VERSION ""

NS_ :

BS_:

BU_: XXX

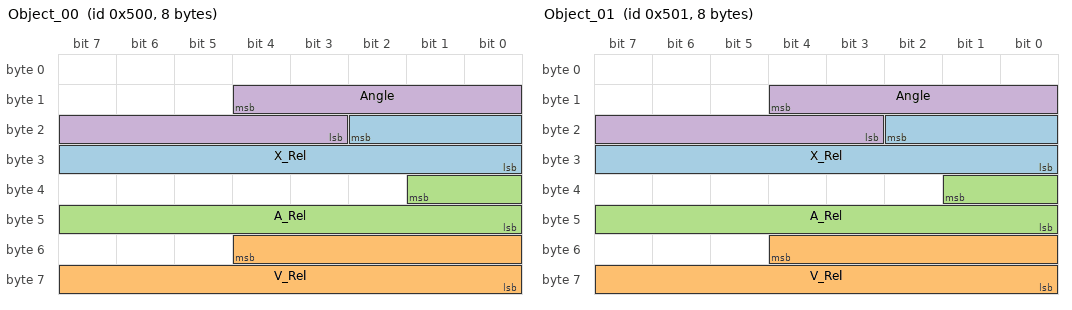
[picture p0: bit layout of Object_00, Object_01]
BO_ 1280 Object_00: 8 XXX
 SG_ X_Rel : 18|11@0+ (0.1,0) [0|0] "m" XXX
 SG_ V_Rel : 52|13@0- (0.01,0) [0|0] "m/s" XXX
 SG_ A_Rel : 33|10@0- (0.05,0) [0|0] "m/s2" XXX
 SG_ Angle : 12|10@0- (-0.1,0) [0|0] "deg" XXX

BO_ 1281 Object_01: 8 XXX
 SG_ X_Rel : 18|11@0+ (0.1,0) [0|0] "m" XXX
 SG_ V_Rel : 52|13@0- (0.01,0) [0|0] "m/s" XXX
 SG_ A_Rel : 33|10@0- (0.05,0) [0|0] "m/s2" XXX
 SG_ Angle : 12|10@0- (-0.1,0) [0|0] "deg" XXX

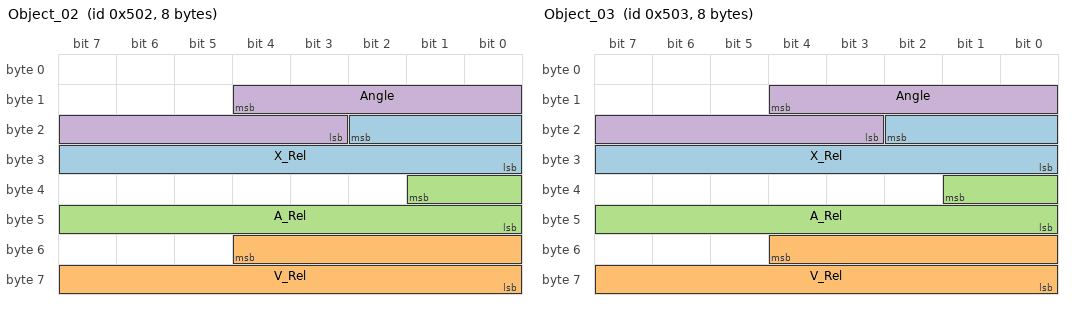
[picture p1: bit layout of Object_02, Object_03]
BO_ 1282 Object_02: 8 XXX
 SG_ X_Rel : 18|11@0+ (0.1,0) [0|0] "m" XXX
 SG_ V_Rel : 52|13@0- (0.01,0) [0|0] "m/s" XXX
 SG_ A_Rel : 33|10@0- (0.05,0) [0|0] "m/s2" XXX
 SG_ Angle : 12|10@0- (-0.1,0) [0|0] "deg" XXX

BO_ 1283 Object_03: 8 XXX
 SG_ X_Rel : 18|11@0+ (0.1,0) [0|0] "m" XXX
 SG_ V_Rel : 52|13@0- (0.01,0) [0|0] "m/s" XXX
 SG_ A_Rel : 33|10@0- (0.05,0) [0|0] "m/s2" XXX
 SG_ Angle : 12|10@0- (-0.1,0) [0|0] "deg" XXX

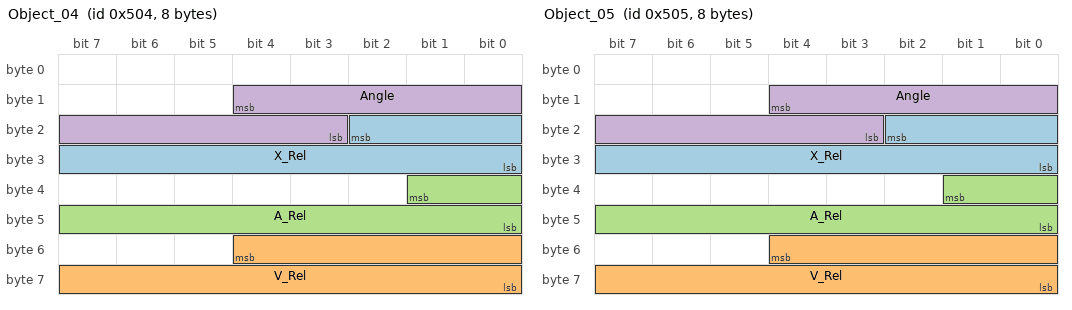
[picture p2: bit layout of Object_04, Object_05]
BO_ 1284 Object_04: 8 XXX
 SG_ X_Rel : 18|11@0+ (0.1,0) [0|0] "m" XXX
 SG_ V_Rel : 52|13@0- (0.01,0) [0|0] "m/s" XXX
 SG_ A_Rel : 33|10@0- (0.05,0) [0|0] "m/s2" XXX
 SG_ Angle : 12|10@0- (-0.1,0) [0|0] "deg" XXX

BO_ 1285 Object_05: 8 XXX
 SG_ X_Rel : 18|11@0+ (0.1,0) [0|0] "m" XXX
 SG_ V_Rel : 52|13@0- (0.01,0) [0|0] "m/s" XXX
 SG_ A_Rel : 33|10@0- (0.05,0) [0|0] "m/s2" XXX
 SG_ Angle : 12|10@0- (-0.1,0) [0|0] "deg" XXX

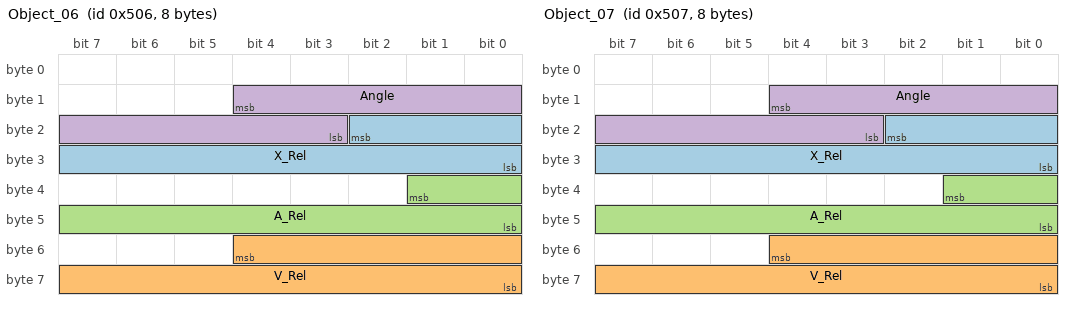
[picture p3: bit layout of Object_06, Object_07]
BO_ 1286 Object_06: 8 XXX
 SG_ X_Rel : 18|11@0+ (0.1,0) [0|0] "m" XXX
 SG_ V_Rel : 52|13@0- (0.01,0) [0|0] "m/s" XXX
 SG_ A_Rel : 33|10@0- (0.05,0) [0|0] "m/s2" XXX
 SG_ Angle : 12|10@0- (-0.1,0) [0|0] "deg" XXX

BO_ 1287 Object_07: 8 XXX
 SG_ X_Rel : 18|11@0+ (0.1,0) [0|0] "m" XXX
 SG_ V_Rel : 52|13@0- (0.01,0) [0|0] "m/s" XXX
 SG_ A_Rel : 33|10@0- (0.05,0) [0|0] "m/s2" XXX
 SG_ Angle : 12|10@0- (-0.1,0) [0|0] "deg" XXX

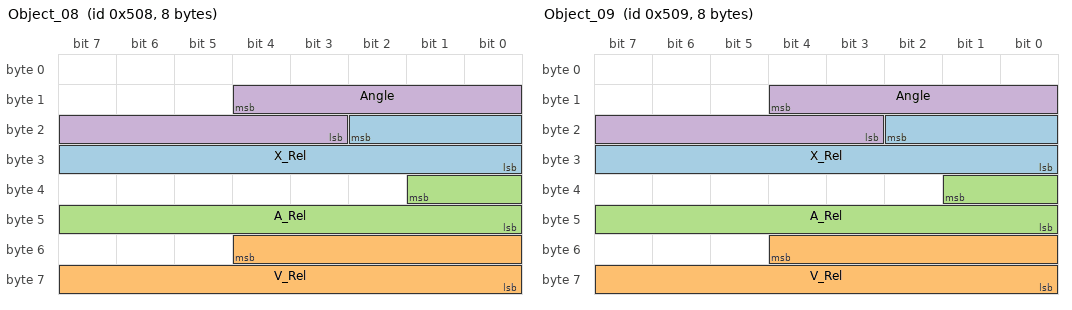
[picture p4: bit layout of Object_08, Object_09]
BO_ 1288 Object_08: 8 XXX
 SG_ X_Rel : 18|11@0+ (0.1,0) [0|0] "m" XXX
 SG_ V_Rel : 52|13@0- (0.01,0) [0|0] "m/s" XXX
 SG_ A_Rel : 33|10@0- (0.05,0) [0|0] "m/s2" XXX
 SG_ Angle : 12|10@0- (-0.1,0) [0|0] "deg" XXX

BO_ 1289 Object_09: 8 XXX
 SG_ X_Rel : 18|11@0+ (0.1,0) [0|0] "m" XXX
 SG_ V_Rel : 52|13@0- (0.01,0) [0|0] "m/s" XXX
 SG_ A_Rel : 33|10@0- (0.05,0) [0|0] "m/s2" XXX
 SG_ Angle : 12|10@0- (-0.1,0) [0|0] "deg" XXX

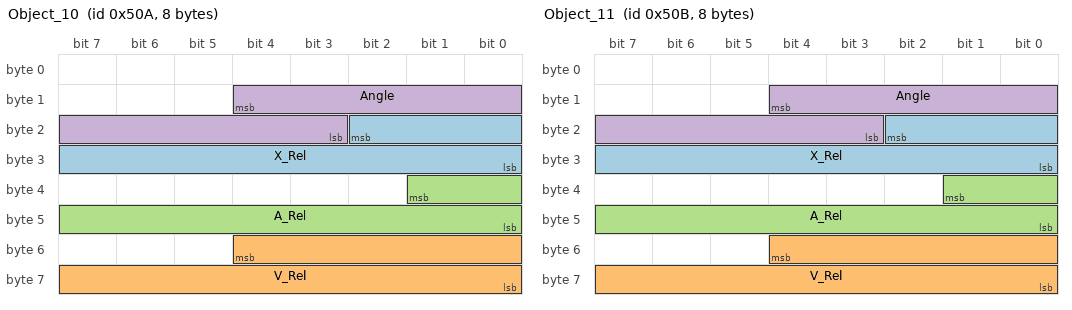
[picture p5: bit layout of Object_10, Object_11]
BO_ 1290 Object_10: 8 XXX
 SG_ X_Rel : 18|11@0+ (0.1,0) [0|0] "m" XXX
 SG_ V_Rel : 52|13@0- (0.01,0) [0|0] "m/s" XXX
 SG_ A_Rel : 33|10@0- (0.05,0) [0|0] "m/s2" XXX
 SG_ Angle : 12|10@0- (-0.1,0) [0|0] "deg" XXX

BO_ 1291 Object_11: 8 XXX
 SG_ X_Rel : 18|11@0+ (0.1,0) [0|0] "m" XXX
 SG_ V_Rel : 52|13@0- (0.01,0) [0|0] "m/s" XXX
 SG_ A_Rel : 33|10@0- (0.05,0) [0|0] "m/s2" XXX
 SG_ Angle : 12|10@0- (-0.1,0) [0|0] "deg" XXX

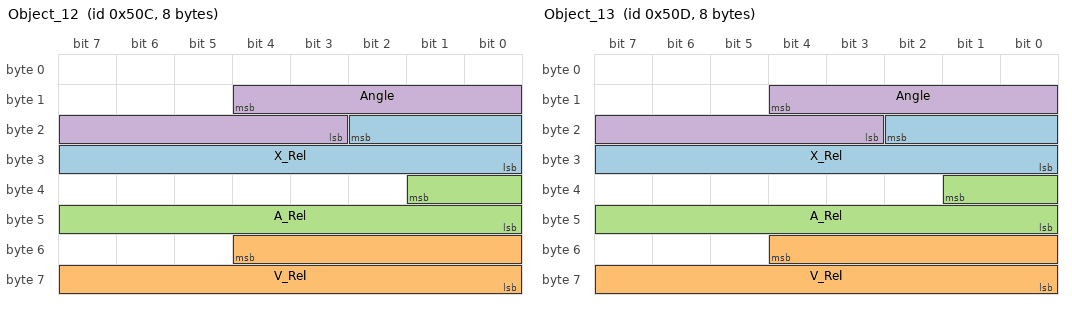
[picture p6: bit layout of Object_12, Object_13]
BO_ 1292 Object_12: 8 XXX
 SG_ X_Rel : 18|11@0+ (0.1,0) [0|0] "m" XXX
 SG_ V_Rel : 52|13@0- (0.01,0) [0|0] "m/s" XXX
 SG_ A_Rel : 33|10@0- (0.05,0) [0|0] "m/s2" XXX
 SG_ Angle : 12|10@0- (-0.1,0) [0|0] "deg" XXX

BO_ 1293 Object_13: 8 XXX
 SG_ X_Rel : 18|11@0+ (0.1,0) [0|0] "m" XXX
 SG_ V_Rel : 52|13@0- (0.01,0) [0|0] "m/s" XXX
 SG_ A_Rel : 33|10@0- (0.05,0) [0|0] "m/s2" XXX
 SG_ Angle : 12|10@0- (-0.1,0) [0|0] "deg" XXX

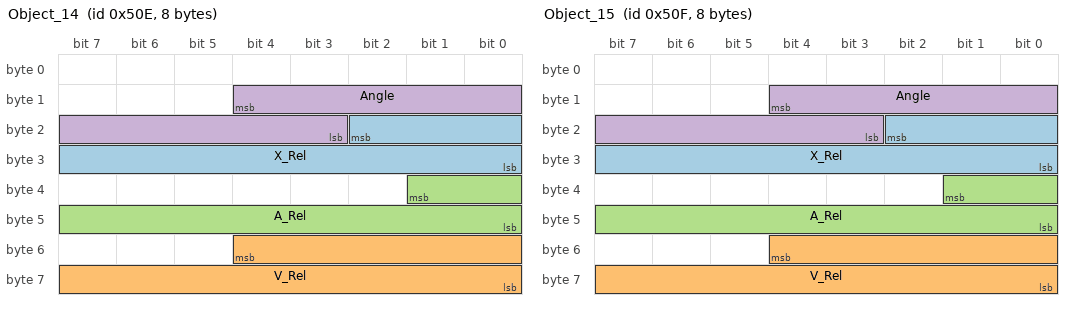
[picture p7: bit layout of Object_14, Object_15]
BO_ 1294 Object_14: 8 XXX
 SG_ X_Rel : 18|11@0+ (0.1,0) [0|0] "m" XXX
 SG_ V_Rel : 52|13@0- (0.01,0) [0|0] "m/s" XXX
 SG_ A_Rel : 33|10@0- (0.05,0) [0|0] "m/s2" XXX
 SG_ Angle : 12|10@0- (-0.1,0) [0|0] "deg" XXX

BO_ 1295 Object_15: 8 XXX
 SG_ X_Rel : 18|11@0+ (0.1,0) [0|0] "m" XXX
 SG_ V_Rel : 52|13@0- (0.01,0) [0|0] "m/s" XXX
 SG_ A_Rel : 33|10@0- (0.05,0) [0|0] "m/s2" XXX
 SG_ Angle : 12|10@0- (-0.1,0) [0|0] "deg" XXX

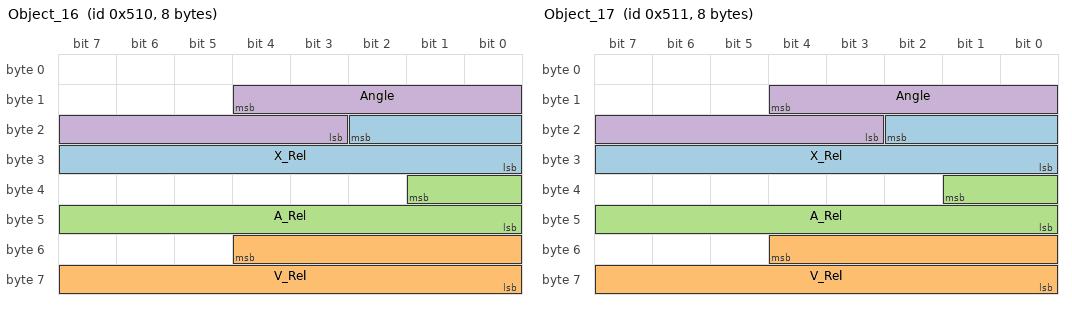
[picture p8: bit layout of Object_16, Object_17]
BO_ 1296 Object_16: 8 XXX
 SG_ X_Rel : 18|11@0+ (0.1,0) [0|0] "m" XXX
 SG_ V_Rel : 52|13@0- (0.01,0) [0|0] "m/s" XXX
 SG_ A_Rel : 33|10@0- (0.05,0) [0|0] "m/s2" XXX
 SG_ Angle : 12|10@0- (-0.1,0) [0|0] "deg" XXX

BO_ 1297 Object_17: 8 XXX
 SG_ X_Rel : 18|11@0+ (0.1,0) [0|0] "m" XXX
 SG_ V_Rel : 52|13@0- (0.01,0) [0|0] "m/s" XXX
 SG_ A_Rel : 33|10@0- (0.05,0) [0|0] "m/s2" XXX
 SG_ Angle : 12|10@0- (-0.1,0) [0|0] "deg" XXX

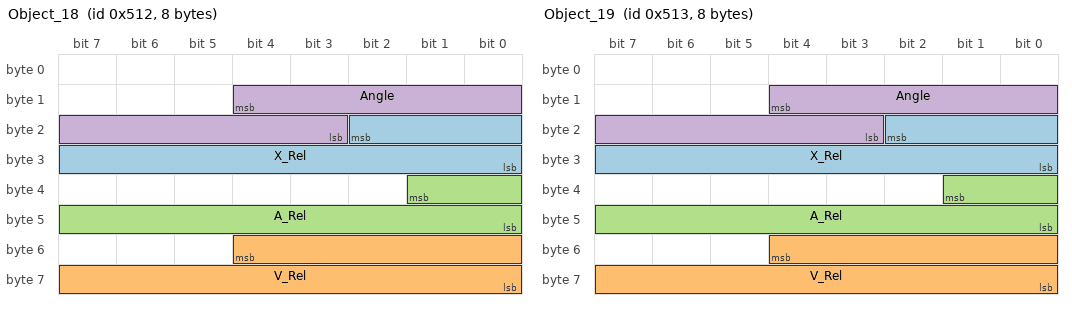
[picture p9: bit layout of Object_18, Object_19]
BO_ 1298 Object_18: 8 XXX
 SG_ X_Rel : 18|11@0+ (0.1,0) [0|0] "m" XXX
 SG_ V_Rel : 52|13@0- (0.01,0) [0|0] "m/s" XXX
 SG_ A_Rel : 33|10@0- (0.05,0) [0|0] "m/s2" XXX
 SG_ Angle : 12|10@0- (-0.1,0) [0|0] "deg" XXX

BO_ 1299 Object_19: 8 XXX
 SG_ X_Rel : 18|11@0+ (0.1,0) [0|0] "m" XXX
 SG_ V_Rel : 52|13@0- (0.01,0) [0|0] "m/s" XXX
 SG_ A_Rel : 33|10@0- (0.05,0) [0|0] "m/s2" XXX
 SG_ Angle : 12|10@0- (-0.1,0) [0|0] "deg" XXX

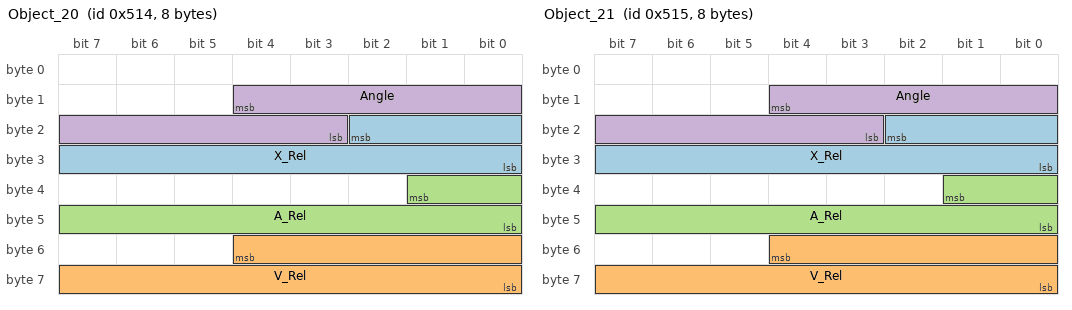
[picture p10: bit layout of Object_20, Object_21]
BO_ 1300 Object_20: 8 XXX
 SG_ X_Rel : 18|11@0+ (0.1,0) [0|0] "m" XXX
 SG_ V_Rel : 52|13@0- (0.01,0) [0|0] "m/s" XXX
 SG_ A_Rel : 33|10@0- (0.05,0) [0|0] "m/s2" XXX
 SG_ Angle : 12|10@0- (-0.1,0) [0|0] "deg" XXX

BO_ 1301 Object_21: 8 XXX
 SG_ X_Rel : 18|11@0+ (0.1,0) [0|0] "m" XXX
 SG_ V_Rel : 52|13@0- (0.01,0) [0|0] "m/s" XXX
 SG_ A_Rel : 33|10@0- (0.05,0) [0|0] "m/s2" XXX
 SG_ Angle : 12|10@0- (-0.1,0) [0|0] "deg" XXX

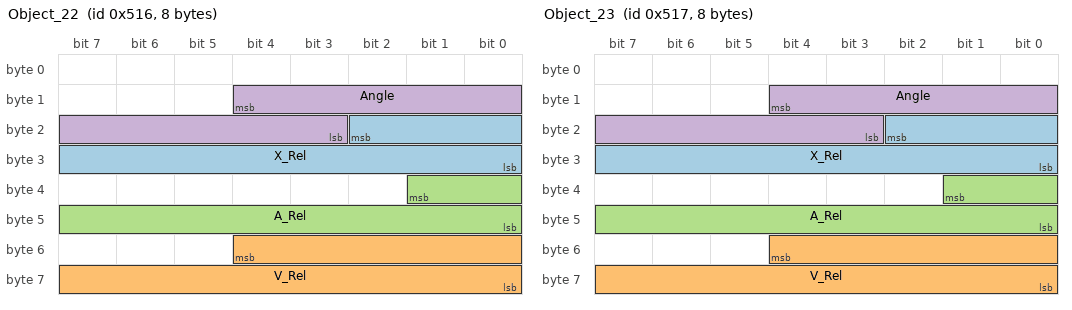
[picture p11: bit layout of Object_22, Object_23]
BO_ 1302 Object_22: 8 XXX
 SG_ X_Rel : 18|11@0+ (0.1,0) [0|0] "m" XXX
 SG_ V_Rel : 52|13@0- (0.01,0) [0|0] "m/s" XXX
 SG_ A_Rel : 33|10@0- (0.05,0) [0|0] "m/s2" XXX
 SG_ Angle : 12|10@0- (-0.1,0) [0|0] "deg" XXX

BO_ 1303 Object_23: 8 XXX
 SG_ X_Rel : 18|11@0+ (0.1,0) [0|0] "m" XXX
 SG_ V_Rel : 52|13@0- (0.01,0) [0|0] "m/s" XXX
 SG_ A_Rel : 33|10@0- (0.05,0) [0|0] "m/s2" XXX
 SG_ Angle : 12|10@0- (-0.1,0) [0|0] "deg" XXX

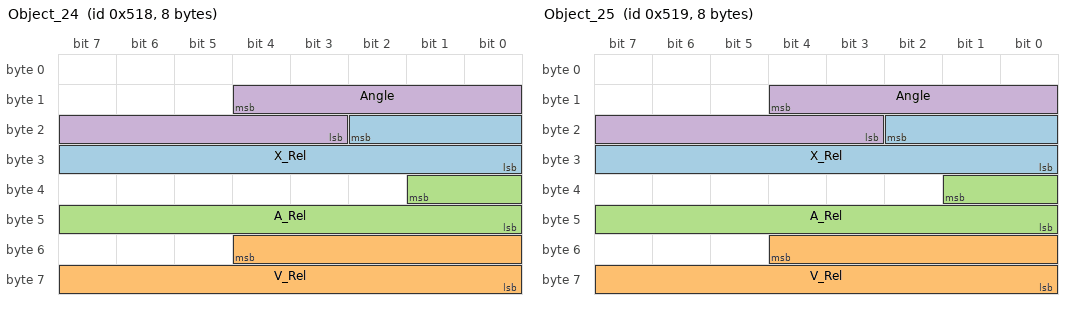
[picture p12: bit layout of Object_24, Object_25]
BO_ 1304 Object_24: 8 XXX
 SG_ X_Rel : 18|11@0+ (0.1,0) [0|0] "m" XXX
 SG_ V_Rel : 52|13@0- (0.01,0) [0|0] "m/s" XXX
 SG_ A_Rel : 33|10@0- (0.05,0) [0|0] "m/s2" XXX
 SG_ Angle : 12|10@0- (-0.1,0) [0|0] "deg" XXX

BO_ 1305 Object_25: 8 XXX
 SG_ X_Rel : 18|11@0+ (0.1,0) [0|0] "m" XXX
 SG_ V_Rel : 52|13@0- (0.01,0) [0|0] "m/s" XXX
 SG_ A_Rel : 33|10@0- (0.05,0) [0|0] "m/s2" XXX
 SG_ Angle : 12|10@0- (-0.1,0) [0|0] "deg" XXX

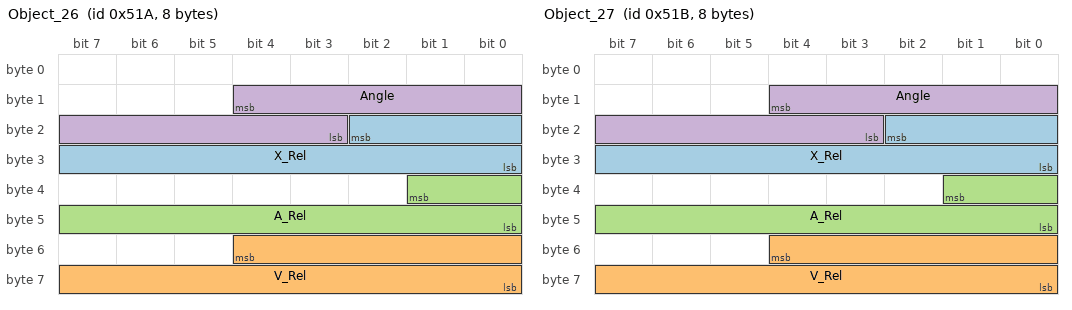
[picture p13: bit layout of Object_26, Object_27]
BO_ 1306 Object_26: 8 XXX
 SG_ X_Rel : 18|11@0+ (0.1,0) [0|0] "m" XXX
 SG_ V_Rel : 52|13@0- (0.01,0) [0|0] "m/s" XXX
 SG_ A_Rel : 33|10@0- (0.05,0) [0|0] "m/s2" XXX
 SG_ Angle : 12|10@0- (-0.1,0) [0|0] "deg" XXX

BO_ 1307 Object_27: 8 XXX
 SG_ X_Rel : 18|11@0+ (0.1,0) [0|0] "m" XXX
 SG_ V_Rel : 52|13@0- (0.01,0) [0|0] "m/s" XXX
 SG_ A_Rel : 33|10@0- (0.05,0) [0|0] "m/s2" XXX
 SG_ Angle : 12|10@0- (-0.1,0) [0|0] "deg" XXX

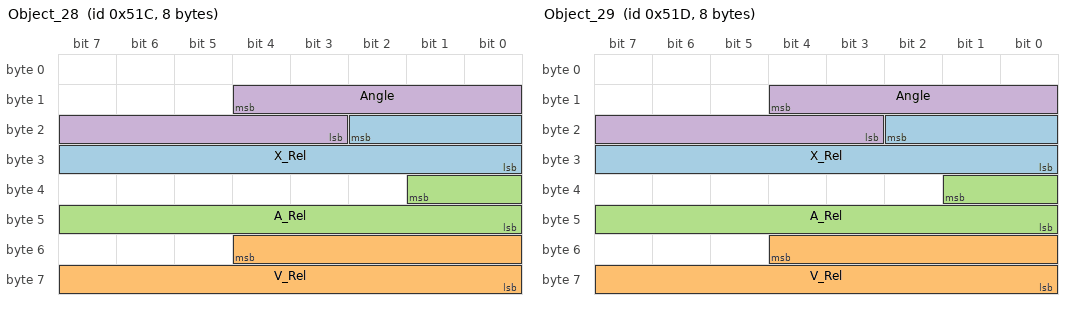
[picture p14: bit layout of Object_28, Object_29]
BO_ 1308 Object_28: 8 XXX
 SG_ X_Rel : 18|11@0+ (0.1,0) [0|0] "m" XXX
 SG_ V_Rel : 52|13@0- (0.01,0) [0|0] "m/s" XXX
 SG_ A_Rel : 33|10@0- (0.05,0) [0|0] "m/s2" XXX
 SG_ Angle : 12|10@0- (-0.1,0) [0|0] "deg" XXX

BO_ 1309 Object_29: 8 XXX
 SG_ X_Rel : 18|11@0+ (0.1,0) [0|0] "m" XXX
 SG_ V_Rel : 52|13@0- (0.01,0) [0|0] "m/s" XXX
 SG_ A_Rel : 33|10@0- (0.05,0) [0|0] "m/s2" XXX
 SG_ Angle : 12|10@0- (-0.1,0) [0|0] "deg" XXX

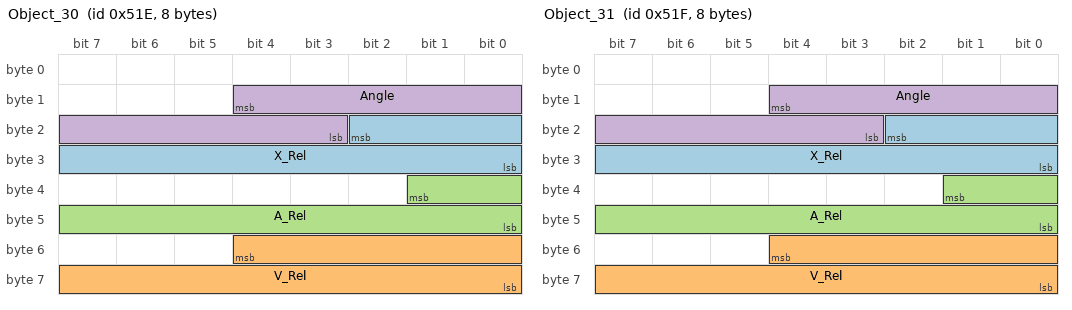
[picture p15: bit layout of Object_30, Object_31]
BO_ 1310 Object_30: 8 XXX
 SG_ X_Rel : 18|11@0+ (0.1,0) [0|0] "m" XXX
 SG_ V_Rel : 52|13@0- (0.01,0) [0|0] "m/s" XXX
 SG_ A_Rel : 33|10@0- (0.05,0) [0|0] "m/s2" XXX
 SG_ Angle : 12|10@0- (-0.1,0) [0|0] "deg" XXX

BO_ 1311 Object_31: 8 XXX
 SG_ X_Rel : 18|11@0+ (0.1,0) [0|0] "m" XXX
 SG_ V_Rel : 52|13@0- (0.01,0) [0|0] "m/s" XXX
 SG_ A_Rel : 33|10@0- (0.05,0) [0|0] "m/s2" XXX
 SG_ Angle : 12|10@0- (-0.1,0) [0|0] "deg" XXX

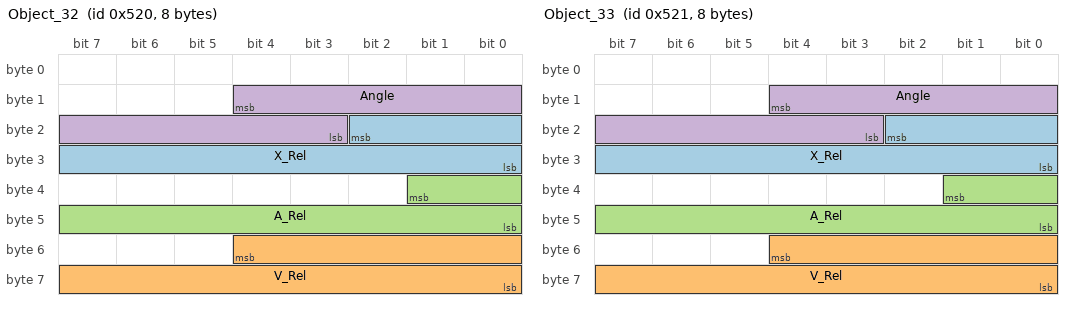
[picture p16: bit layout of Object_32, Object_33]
BO_ 1312 Object_32: 8 XXX
 SG_ X_Rel : 18|11@0+ (0.1,0) [0|0] "m" XXX
 SG_ V_Rel : 52|13@0- (0.01,0) [0|0] "m/s" XXX
 SG_ A_Rel : 33|10@0- (0.05,0) [0|0] "m/s2" XXX
 SG_ Angle : 12|10@0- (-0.1,0) [0|0] "deg" XXX

BO_ 1313 Object_33: 8 XXX
 SG_ X_Rel : 18|11@0+ (0.1,0) [0|0] "m" XXX
 SG_ V_Rel : 52|13@0- (0.01,0) [0|0] "m/s" XXX
 SG_ A_Rel : 33|10@0- (0.05,0) [0|0] "m/s2" XXX
 SG_ Angle : 12|10@0- (-0.1,0) [0|0] "deg" XXX

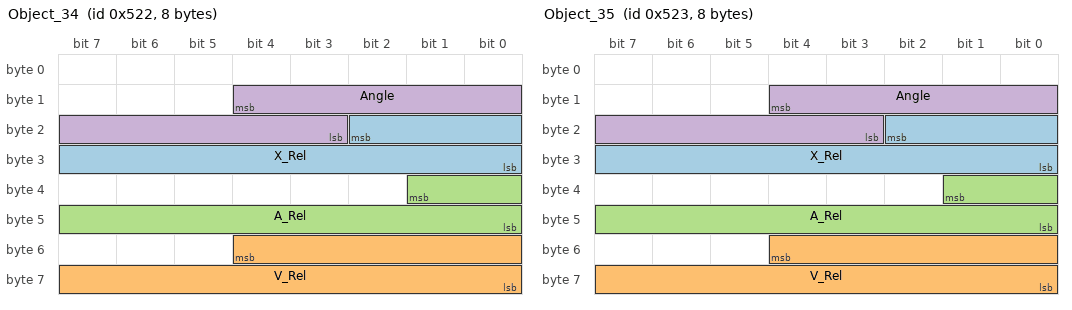
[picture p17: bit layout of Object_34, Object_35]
BO_ 1314 Object_34: 8 XXX
 SG_ X_Rel : 18|11@0+ (0.1,0) [0|0] "m" XXX
 SG_ V_Rel : 52|13@0- (0.01,0) [0|0] "m/s" XXX
 SG_ A_Rel : 33|10@0- (0.05,0) [0|0] "m/s2" XXX
 SG_ Angle : 12|10@0- (-0.1,0) [0|0] "deg" XXX

BO_ 1315 Object_35: 8 XXX
 SG_ X_Rel : 18|11@0+ (0.1,0) [0|0] "m" XXX
 SG_ V_Rel : 52|13@0- (0.01,0) [0|0] "m/s" XXX
 SG_ A_Rel : 33|10@0- (0.05,0) [0|0] "m/s2" XXX
 SG_ Angle : 12|10@0- (-0.1,0) [0|0] "deg" XXX

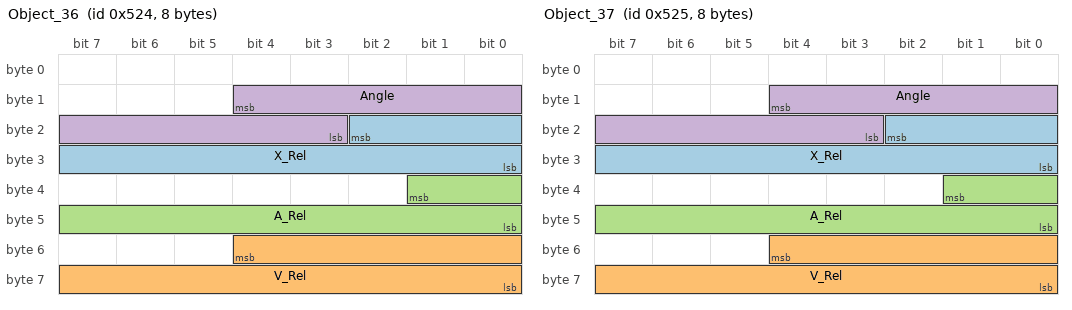
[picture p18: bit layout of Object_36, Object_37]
BO_ 1316 Object_36: 8 XXX
 SG_ X_Rel : 18|11@0+ (0.1,0) [0|0] "m" XXX
 SG_ V_Rel : 52|13@0- (0.01,0) [0|0] "m/s" XXX
 SG_ A_Rel : 33|10@0- (0.05,0) [0|0] "m/s2" XXX
 SG_ Angle : 12|10@0- (-0.1,0) [0|0] "deg" XXX

BO_ 1317 Object_37: 8 XXX
 SG_ X_Rel : 18|11@0+ (0.1,0) [0|0] "m" XXX
 SG_ V_Rel : 52|13@0- (0.01,0) [0|0] "m/s" XXX
 SG_ A_Rel : 33|10@0- (0.05,0) [0|0] "m/s2" XXX
 SG_ Angle : 12|10@0- (-0.1,0) [0|0] "deg" XXX

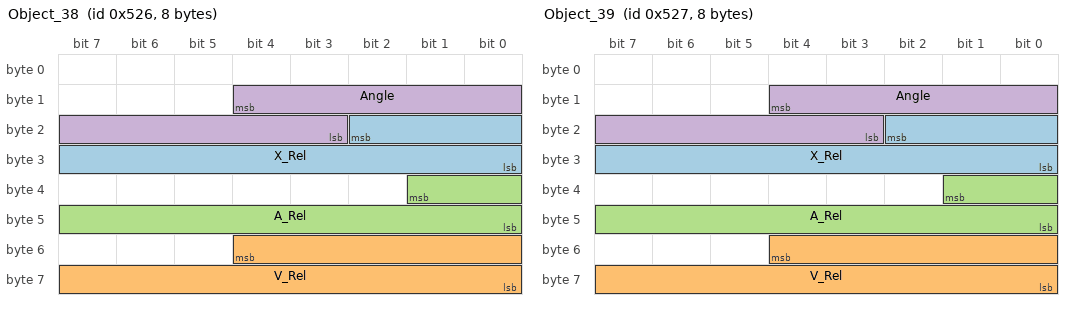
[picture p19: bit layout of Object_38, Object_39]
BO_ 1318 Object_38: 8 XXX
 SG_ X_Rel : 18|11@0+ (0.1,0) [0|0] "m" XXX
 SG_ V_Rel : 52|13@0- (0.01,0) [0|0] "m/s" XXX
 SG_ A_Rel : 33|10@0- (0.05,0) [0|0] "m/s2" XXX
 SG_ Angle : 12|10@0- (-0.1,0) [0|0] "deg" XXX

BO_ 1319 Object_39: 8 XXX
 SG_ X_Rel : 18|11@0+ (0.1,0) [0|0] "m" XXX
 SG_ V_Rel : 52|13@0- (0.01,0) [0|0] "m/s" XXX
 SG_ A_Rel : 33|10@0- (0.05,0) [0|0] "m/s2" XXX
 SG_ Angle : 12|10@0- (-0.1,0) [0|0] "deg" XXX

BO_ 1320 Object_40: 8 XXX
 SG_ X_Rel : 18|11@0+ (0.1,0) [0|0] "m" XXX
 SG_ V_Rel : 52|13@0- (0.01,0) [0|0] "m/s" XXX
 SG_ A_Rel : 33|10@0- (0.05,0) [0|0] "m/s2" XXX
 SG_ Angle : 12|10@0- (-0.1,0) [0|0] "deg" XXX

BO_ 1321 Object_41: 8 XXX
 SG_ X_Rel : 18|11@0+ (0.1,0) [0|0] "m" XXX
 SG_ V_Rel : 52|13@0- (0.01,0) [0|0] "m/s" XXX
 SG_ A_Rel : 33|10@0- (0.05,0) [0|0] "m/s2" XXX
 SG_ Angle : 12|10@0- (-0.1,0) [0|0] "deg" XXX

BO_ 1322 Object_42: 8 XXX
 SG_ X_Rel : 18|11@0+ (0.1,0) [0|0] "m" XXX
 SG_ V_Rel : 52|13@0- (0.01,0) [0|0] "m/s" XXX
 SG_ A_Rel : 33|10@0- (0.05,0) [0|0] "m/s2" XXX
 SG_ Angle : 12|10@0- (-0.1,0) [0|0] "deg" XXX

BO_ 1323 Object_43: 8 XXX
 SG_ X_Rel : 18|11@0+ (0.1,0) [0|0] "m" XXX
 SG_ V_Rel : 52|13@0- (0.01,0) [0|0] "m/s" XXX
 SG_ A_Rel : 33|10@0- (0.05,0) [0|0] "m/s2" XXX
 SG_ Angle : 12|10@0- (-0.1,0) [0|0] "deg" XXX

BO_ 1324 Object_44: 8 XXX
 SG_ X_Rel : 18|11@0+ (0.1,0) [0|0] "m" XXX
 SG_ V_Rel : 52|13@0- (0.01,0) [0|0] "m/s" XXX
 SG_ A_Rel : 33|10@0- (0.05,0) [0|0] "m/s2" XXX
 SG_ Angle : 12|10@0- (-0.1,0) [0|0] "deg" XXX

BO_ 1325 Object_45: 8 XXX
 SG_ X_Rel : 18|11@0+ (0.1,0) [0|0] "m" XXX
 SG_ V_Rel : 52|13@0- (0.01,0) [0|0] "m/s" XXX
 SG_ A_Rel : 33|10@0- (0.05,0) [0|0] "m/s2" XXX
 SG_ Angle : 12|10@0- (-0.1,0) [0|0] "deg" XXX

BO_ 1326 Object_46: 8 XXX
 SG_ X_Rel : 18|11@0+ (0.1,0) [0|0] "m" XXX
 SG_ V_Rel : 52|13@0- (0.01,0) [0|0] "m/s" XXX
 SG_ A_Rel : 33|10@0- (0.05,0) [0|0] "m/s2" XXX
 SG_ Angle : 12|10@0- (-0.1,0) [0|0] "deg" XXX

BO_ 1327 Object_47: 8 XXX
 SG_ X_Rel : 18|11@0+ (0.1,0) [0|0] "m" XXX
 SG_ V_Rel : 52|13@0- (0.01,0) [0|0] "m/s" XXX
 SG_ A_Rel : 33|10@0- (0.05,0) [0|0] "m/s2" XXX
 SG_ Angle : 12|10@0- (-0.1,0) [0|0] "deg" XXX

BO_ 1328 Object_48: 8 XXX
 SG_ X_Rel : 18|11@0+ (0.1,0) [0|0] "m" XXX
 SG_ V_Rel : 52|13@0- (0.01,0) [0|0] "m/s" XXX
 SG_ A_Rel : 33|10@0- (0.05,0) [0|0] "m/s2" XXX
 SG_ Angle : 12|10@0- (-0.1,0) [0|0] "deg" XXX

BO_ 1329 Object_49: 8 XXX
 SG_ X_Rel : 18|11@0+ (0.1,0) [0|0] "m" XXX
 SG_ V_Rel : 52|13@0- (0.01,0) [0|0] "m/s" XXX
 SG_ A_Rel : 33|10@0- (0.05,0) [0|0] "m/s2" XXX
 SG_ Angle : 12|10@0- (-0.1,0) [0|0] "deg" XXX

BO_ 1330 Object_50: 8 XXX
 SG_ X_Rel : 18|11@0+ (0.1,0) [0|0] "m" XXX
 SG_ V_Rel : 52|13@0- (0.01,0) [0|0] "m/s" XXX
 SG_ A_Rel : 33|10@0- (0.05,0) [0|0] "m/s2" XXX
 SG_ Angle : 12|10@0- (-0.1,0) [0|0] "deg" XXX

BO_ 1331 Object_51: 8 XXX
 SG_ X_Rel : 18|11@0+ (0.1,0) [0|0] "m" XXX
 SG_ V_Rel : 52|13@0- (0.01,0) [0|0] "m/s" XXX
 SG_ A_Rel : 33|10@0- (0.05,0) [0|0] "m/s2" XXX
 SG_ Angle : 12|10@0- (-0.1,0) [0|0] "deg" XXX

BO_ 1332 Object_52: 8 XXX
 SG_ X_Rel : 18|11@0+ (0.1,0) [0|0] "m" XXX
 SG_ V_Rel : 52|13@0- (0.01,0) [0|0] "m/s" XXX
 SG_ A_Rel : 33|10@0- (0.05,0) [0|0] "m/s2" XXX
 SG_ Angle : 12|10@0- (-0.1,0) [0|0] "deg" XXX

BO_ 1333 Object_53: 8 XXX
 SG_ X_Rel : 18|11@0+ (0.1,0) [0|0] "m" XXX
 SG_ V_Rel : 52|13@0- (0.01,0) [0|0] "m/s" XXX
 SG_ A_Rel : 33|10@0- (0.05,0) [0|0] "m/s2" XXX
 SG_ Angle : 12|10@0- (-0.1,0) [0|0] "deg" XXX

BO_ 1334 Object_54: 8 XXX
 SG_ X_Rel : 18|11@0+ (0.1,0) [0|0] "m" XXX
 SG_ V_Rel : 52|13@0- (0.01,0) [0|0] "m/s" XXX
 SG_ A_Rel : 33|10@0- (0.05,0) [0|0] "m/s2" XXX
 SG_ Angle : 12|10@0- (-0.1,0) [0|0] "deg" XXX

BO_ 1335 Object_55: 8 XXX
 SG_ X_Rel : 18|11@0+ (0.1,0) [0|0] "m" XXX
 SG_ V_Rel : 52|13@0- (0.01,0) [0|0] "m/s" XXX
 SG_ A_Rel : 33|10@0- (0.05,0) [0|0] "m/s2" XXX
 SG_ Angle : 12|10@0- (-0.1,0) [0|0] "deg" XXX

BO_ 1336 Object_56: 8 XXX
 SG_ X_Rel : 18|11@0+ (0.1,0) [0|0] "m" XXX
 SG_ V_Rel : 52|13@0- (0.01,0) [0|0] "m/s" XXX
 SG_ A_Rel : 33|10@0- (0.05,0) [0|0] "m/s2" XXX
 SG_ Angle : 12|10@0- (-0.1,0) [0|0] "deg" XXX

BO_ 1337 Object_57: 8 XXX
 SG_ X_Rel : 18|11@0+ (0.1,0) [0|0] "m" XXX
 SG_ V_Rel : 52|13@0- (0.01,0) [0|0] "m/s" XXX
 SG_ A_Rel : 33|10@0- (0.05,0) [0|0] "m/s2" XXX
 SG_ Angle : 12|10@0- (-0.1,0) [0|0] "deg" XXX

BO_ 1338 Object_58: 8 XXX
 SG_ X_Rel : 18|11@0+ (0.1,0) [0|0] "m" XXX
 SG_ V_Rel : 52|13@0- (0.01,0) [0|0] "m/s" XXX
 SG_ A_Rel : 33|10@0- (0.05,0) [0|0] "m/s2" XXX
 SG_ Angle : 12|10@0- (-0.1,0) [0|0] "deg" XXX

BO_ 1339 Object_59: 8 XXX
 SG_ X_Rel : 18|11@0+ (0.1,0) [0|0] "m" XXX
 SG_ V_Rel : 52|13@0- (0.01,0) [0|0] "m/s" XXX
 SG_ A_Rel : 33|10@0- (0.05,0) [0|0] "m/s2" XXX
 SG_ Angle : 12|10@0- (-0.1,0) [0|0] "deg" XXX

BO_ 1340 Object_60: 8 XXX
 SG_ X_Rel : 18|11@0+ (0.1,0) [0|0] "m" XXX
 SG_ V_Rel : 52|13@0- (0.01,0) [0|0] "m/s" XXX
 SG_ A_Rel : 33|10@0- (0.05,0) [0|0] "m/s2" XXX
 SG_ Angle : 12|10@0- (-0.1,0) [0|0] "deg" XXX

BO_ 1341 Object_61: 8 XXX
 SG_ X_Rel : 18|11@0+ (0.1,0) [0|0] "m" XXX
 SG_ V_Rel : 52|13@0- (0.01,0) [0|0] "m/s" XXX
 SG_ A_Rel : 33|10@0- (0.05,0) [0|0] "m/s2" XXX
 SG_ Angle : 12|10@0- (-0.1,0) [0|0] "deg" XXX

BO_ 1342 Object_62: 8 XXX
 SG_ X_Rel : 18|11@0+ (0.1,0) [0|0] "m" XXX
 SG_ V_Rel : 52|13@0- (0.01,0) [0|0] "m/s" XXX
 SG_ A_Rel : 33|10@0- (0.05,0) [0|0] "m/s2" XXX
 SG_ Angle : 12|10@0- (-0.1,0) [0|0] "deg" XXX

BO_ 1343 Object_63: 8 XXX
 SG_ X_Rel : 18|11@0+ (0.1,0) [0|0] "m" XXX
 SG_ V_Rel : 52|13@0- (0.01,0) [0|0] "m/s" XXX
 SG_ A_Rel : 33|10@0- (0.05,0) [0|0] "m/s2" XXX
 SG_ Angle : 12|10@0- (-0.1,0) [0|0] "deg" XXX
